AUTOSAR XML (schema 00044)
package /ComponentTypes
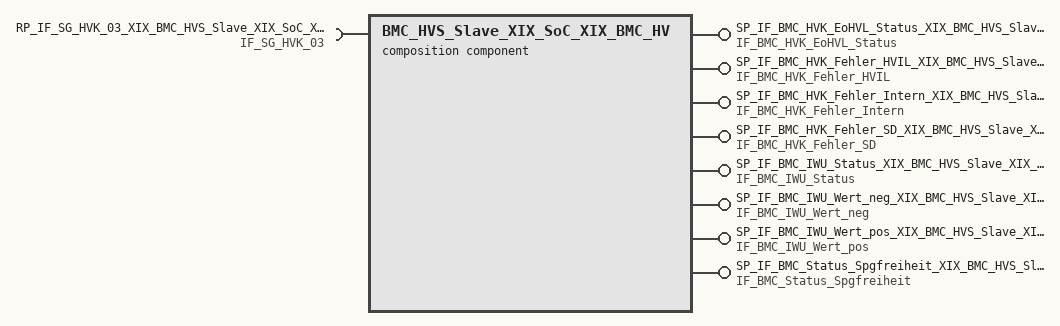
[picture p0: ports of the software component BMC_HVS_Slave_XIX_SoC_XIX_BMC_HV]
  composition sw component type BMC_HVS_Slave_XIX_SoC_XIX_BMC_HV
    8 x provide port:
      SP_IF_BMC_HVK_EoHVL_Status_XIX_BMC_HVS_Slave_XIX_SoC_XIX_BMC_HV: nonqueued-sender-com-spec=DE_BMC_HVK_EoHVL_Status, provided-interface=IF_BMC_HVK_EoHVL_Status
      SP_IF_BMC_HVK_Fehler_HVIL_XIX_BMC_HVS_Slave_XIX_SoC_XIX_BMC_HV: nonqueued-sender-com-spec=DE_BMC_HVK_Fehler_HVIL, provided-interface=IF_BMC_HVK_Fehler_HVIL
      SP_IF_BMC_HVK_Fehler_Intern_XIX_BMC_HVS_Slave_XIX_SoC_XIX_BMC_HV: nonqueued-sender-com-spec=DE_BMC_HVK_Fehler_Intern, provided-interface=IF_BMC_HVK_Fehler_Intern
      SP_IF_BMC_HVK_Fehler_SD_XIX_BMC_HVS_Slave_XIX_SoC_XIX_BMC_HV: nonqueued-sender-com-spec=DE_BMC_HVK_Fehler_SD, provided-interface=IF_BMC_HVK_Fehler_SD
      SP_IF_BMC_IWU_Status_XIX_BMC_HVS_Slave_XIX_SoC_XIX_BMC_HV: nonqueued-sender-com-spec=DE_BMC_IWU_Status, provided-interface=IF_BMC_IWU_Status
      SP_IF_BMC_IWU_Wert_neg_XIX_BMC_HVS_Slave_XIX_SoC_XIX_BMC_HV: nonqueued-sender-com-spec=DE_BMC_IWU_Wert_neg, provided-interface=IF_BMC_IWU_Wert_neg
      SP_IF_BMC_IWU_Wert_pos_XIX_BMC_HVS_Slave_XIX_SoC_XIX_BMC_HV: nonqueued-sender-com-spec=DE_BMC_IWU_Wert_pos, provided-interface=IF_BMC_IWU_Wert_pos
      SP_IF_BMC_Status_Spgfreiheit_XIX_BMC_HVS_Slave_XIX_SoC_XIX_BMC_HV: nonqueued-sender-com-spec=DE_BMC_Status_Spgfreiheit, provided-interface=IF_BMC_Status_Spgfreiheit
    require port RP_IF_SG_HVK_03_XIX_BMC_HVS_Slave_XIX_SoC_XIX_BMC_HV: nonqueued-receiver-com-spec=DE_SG_HVK_03, required-interface=IF_SG_HVK_03
